# GAP8 register map
Vendor: GreenWaves Technologies SAS; Series: GAP8; File version: 1.3.1
CPU: other r1p0, little endian, MPU, no FPU, I-cache, DTCM, false interrupt priority bits
Registers are 32-bit, read-write, reset 0x0 unless marked. A register's access mark holds for its fields unless they carry their own. Offsets are from the block's base; [hi:lo] are bit positions; 'fields as' and 'values as' point back to an identical list.

## soc_fll
Base 0x1A100000
Same registers: cluster_fll 0x1A100800
0x00 status — FLL status register.
  [15:0] mf ro — Current DCO multiplication factor value bitfield.
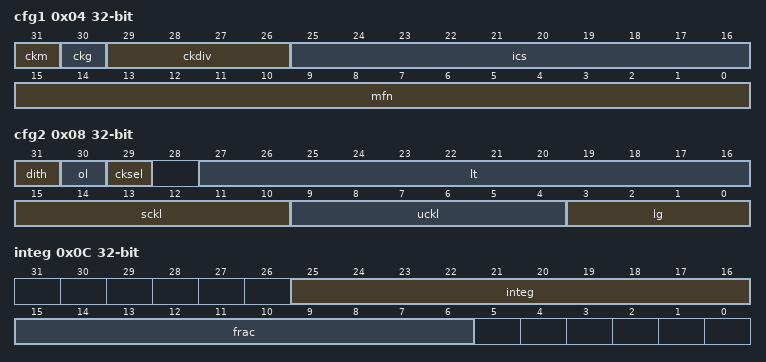
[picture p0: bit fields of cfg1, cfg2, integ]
0x04 cfg1 — FLL configuration 1 register.
  [31] ckm — FLL operation mode configuration bitfield
    0=standalone (set to standalone); 1=normal (set to normal)
  [30] ckg — FLL output gated by LOCK signal configuration bitfield
    0=not_gated (set to not gated); 1=gated (set to gated)
  [29:26] ckdiv — FLL output clock divider configuration bitfield.
  [25:16] ics — DCO input code in standalone mode bitfield.
  [15:0] mfn — Target clock multiplication factor in normal mode bitfield.
0x08 cfg2 — FLL configuration 2 register.
  [31] dith — Dithering activation bitfield
    0=disabled (feature is disabled); 1=enabled (feature is enabled)
  [30] ol — Open loop when locked activation bitfield
    values as dith
  [29] cksel — Configuration clock selection in standalone mode bitfield
    0=dco_clock (set to DCO clock); 1=reference_clock (set to Reference clock)
  [27:16] lt — Lock tolerance configuration bitfield. It is the margin around multiplication factor within which the output clock is considered stable.
  [15:10] sckl — Number of stable REFCLK cycles until LOCK assert in normal mode. Upper 6-bit of LOCK assert counter target in standalone mode.
  [9:4] uckl — Number of unstable REFCLK cycles until LOCK de-assert in normal mode. Lower 6-bit of LOCK assert counter target in standalone mode.
  [3:0] lg — FLL loop gain setting bitfield.
0x0C integ — FLL integrator configuration register.
  [25:16] integ — integer part of integrator state bitfield. It corresponds to DCO unit bits.
  [15:6] frac — Fractional part of integrator state bitfield. It corresponds to dither unit input.

## soc_event_generator
Base 0x1A106000
0x00 sw_event wo — SoC software events trigger command register.
  [7:0] event — Writing a one-hot value into EVENT bitfield triggers SoC software event i. 8 software events are provided.
0x04 fc_mask_msb reset 0xFFFFFFFF — MSB FC event unit event dispatch mask configuration register.
  [31:0] fc_mask_msb — MSB event mask to enable/disable event dispatch to FC event unit. - Setting bit[i] to 1'b1 disable dispatching event[32+i] to FC event unit. - Setting bit[i] to 1'b0 enable dispatching event[32+i] to FC event unit.
0x08 fc_mask_lsb reset 0xFFFFFFFF — LSB FC event unit event dispatch mask configuration register.
  [31:0] fc_mask_lsb — LSB event mask to enable/disable event dispatch to FC event unit. - Setting bit[i] to 1'b1 disable dispatching event[i] to FC event unit. - Setting bit[i] to 1'b0 enable dispatching event[i] to FC event unit.
0x0C cl_mask_msb reset 0xFFFFFFFF — MSB Cluster event dispatch mask configuration register.
  [31:0] cl_mask_msb — MSB event mask to enable/disable event dispatch to Cluster event unit. - Setting bit[i] to 1'b1 disable dispatching event[32+i] to Cluster event unit. - Setting bit[i] to 1'b0 enable dispatching event[32+i] to Cluster event unit.
0x10 cl_mask_lsb reset 0xFFFFFFFF — LSB Cluster event dispatch mask configuration register.
  [31:0] cl_mask_lsb — LSB event mask to enable/disable event dispatch to Cluster event unit. - Setting bit[i] to 1'b1 disable dispatching event[i] to Cluster event unit. - Setting bit[i] to 1'b0 enable dispatching event[i] to Cluster event unit.
0x14 pr_mask_msb reset 0xFFFFFFFF — MSB uDMA event dispatch mask configuration register.
  [31:0] pr_mask_msb — MSB event mask to enable/disable event dispatch to UDMA peripherals. - Setting bit[i] to 1'b1 disable dispatching event[32+i] to uDMA. - Setting bit[i] to 1'b0 enable dispatching event[32+i] to uDMA.
0x18 pr_mask_lsb reset 0xFFFFFFFF — LSB uDMA event dispatch mask configuration register.
  [31:0] pr_mask_lsb — LSB event mask to enable/disable event dispatch to UDMA peripherals. - Setting bit[i] to 1'b1 disable dispatching event[i] to uDMA. - Setting bit[i] to 1'b0 enable dispatching event[i] to uDMA.
0x1C err_msb ro — MSB event queue overflow status register.
  [31:0] err_msb — Report MSB event queue overflows. Cleared after read. Reading a 1'b1 at ERR_MSB[i] means that an overflow occurred for SoC event[32+i] FIFO queue.
0x20 err_lsb ro — LSB event queue overflow status register.
  [31:0] err_lsb — Report LSB event queue overflows. Cleared after read. Reading a 1'b1 at ERR_LSB[i] means that an overflow occurred for SoC event[i] FIFO queue.
0x24 timer_sel_hi — FC High Timer source event configuration register.
  [5:0] timer_sel_hi — Configure which SoC event generator input event is propagated to FC Timer High input trigger event.
0x28 timer_sel_lo — FC Low Timer source event configuration register.
  [5:0] timer_sel_lo — Configure which SoC event generator input event is propagated to FC Timer Low input trigger event.
